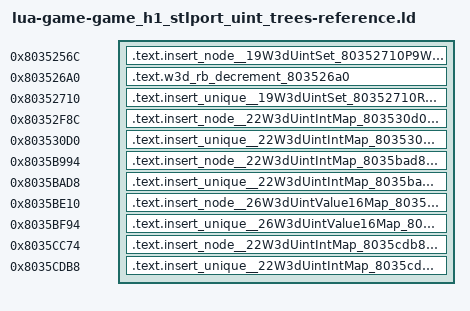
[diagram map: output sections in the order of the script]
/* Generated reference-only placements. All bodies are source-built. */
OUTPUT_FORMAT("elf32-powerpc")
OUTPUT_ARCH(powerpc)
ENTRY(insert_node__19W3dUintSet_80352710P9W3dRbNodeT1RCUiT1)
_SDA_BASE_ = 0x804b2540;
_SDA2_BASE_ = 0x804c2540;
w3d_handle_storage_allocate = 0x80212fd4;
w3d_handle_storage_fallback = 0x803413d8;
w3d_rb_rebalance_80352404 = 0x80352404;
SECTIONS {
  .text.insert_node__19W3dUintSet_80352710P9W3dRbNodeT1RCUiT1 0x8035256c : { *(.text.insert_node__19W3dUintSet_80352710P9W3dRbNodeT1RCUiT1) }
  .text.w3d_rb_decrement_803526a0 0x803526a0 : { *(.text.w3d_rb_decrement_803526a0) }
  .text.insert_unique__19W3dUintSet_80352710RCUi 0x80352710 : { *(.text.insert_unique__19W3dUintSet_80352710RCUi) }
  .text.insert_node__22W3dUintIntMap_803530d0P9W3dRbNodeT1RC14W3dUintIntPairT1 0x80352f8c : { *(.text.insert_node__22W3dUintIntMap_803530d0P9W3dRbNodeT1RC14W3dUintIntPairT1) }
  .text.insert_unique__22W3dUintIntMap_803530d0RC14W3dUintIntPair 0x803530d0 : { *(.text.insert_unique__22W3dUintIntMap_803530d0RC14W3dUintIntPair) }
  .text.insert_node__22W3dUintIntMap_8035bad8P9W3dRbNodeT1RC14W3dUintIntPairT1 0x8035b994 : { *(.text.insert_node__22W3dUintIntMap_8035bad8P9W3dRbNodeT1RC14W3dUintIntPairT1) }
  .text.insert_unique__22W3dUintIntMap_8035bad8RC14W3dUintIntPair 0x8035bad8 : { *(.text.insert_unique__22W3dUintIntMap_8035bad8RC14W3dUintIntPair) }
  .text.insert_node__26W3dUintValue16Map_8035bf94P9W3dRbNodeT1RC18W3dUintValue16PairT1 0x8035be10 : { *(.text.insert_node__26W3dUintValue16Map_8035bf94P9W3dRbNodeT1RC18W3dUintValue16PairT1) }
  .text.insert_unique__26W3dUintValue16Map_8035bf94RC18W3dUintValue16Pair 0x8035bf94 : { *(.text.insert_unique__26W3dUintValue16Map_8035bf94RC18W3dUintValue16Pair) }
  .text.insert_node__22W3dUintIntMap_8035cdb8P9W3dRbNodeT1RC14W3dUintIntPairT1 0x8035cc74 : { *(.text.insert_node__22W3dUintIntMap_8035cdb8P9W3dRbNodeT1RC14W3dUintIntPairT1) }
  .text.insert_unique__22W3dUintIntMap_8035cdb8RC14W3dUintIntPair 0x8035cdb8 : { *(.text.insert_unique__22W3dUintIntMap_8035cdb8RC14W3dUintIntPair) }
  /DISCARD/ : { *(.text*) *(.rodata*) *(.data*) *(.bss*) *(.sdata*) *(.sbss*) *(.comment) }
}
